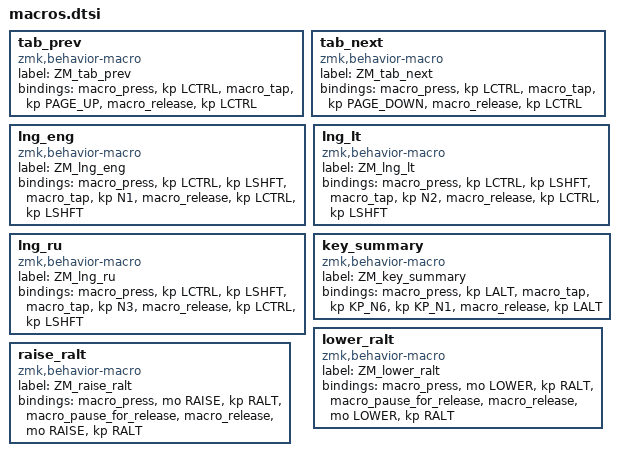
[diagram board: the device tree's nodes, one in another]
 // TAB: PREV
tab_prev: tab_prev {
        label = "ZM_tab_prev";
        compatible = "zmk,behavior-macro";
        #binding-cells = <0>;
        bindings = <&macro_press &kp LCTRL>
                , <&macro_tap &kp PAGE_UP>
                , <&macro_release &kp LCTRL>;
};

// TAB: NEXT
tab_next: tab_next {
        label = "ZM_tab_next";
        compatible = "zmk,behavior-macro";
        #binding-cells = <0>;
        bindings
                = <&macro_press &kp LCTRL>
                , <&macro_tap &kp PAGE_DOWN>
                , <&macro_release &kp LCTRL>;
};

// LANGUAGE: ENG
lng_eng: lng_eng {
        label = "ZM_lng_eng";
        compatible = "zmk,behavior-macro";
        #binding-cells = <0>;
        bindings
                = <&macro_press &kp LCTRL &kp LSHFT>
                , <&macro_tap &kp N1>
                , <&macro_release &kp LCTRL &kp LSHFT>;
};

// LANGUAGE: LT
lng_lt: lng_lt {
        label = "ZM_lng_lt";
        compatible = "zmk,behavior-macro";
        #binding-cells = <0>;
        bindings
                = <&macro_press &kp LCTRL &kp LSHFT>
                , <&macro_tap &kp N2>
                , <&macro_release &kp LCTRL &kp LSHFT>;
};

// LANGUAGE: RU
lng_ru: lng_ru {
        label = "ZM_lng_ru";
        compatible = "zmk,behavior-macro";
        #binding-cells = <0>;
        bindings
                = <&macro_press &kp LCTRL &kp LSHFT>
                , <&macro_tap &kp N3>
                , <&macro_release &kp LCTRL &kp LSHFT>;
};

// ALT CODE: =
key_summary: key_summary {
        label = "ZM_key_summary";
        compatible = "zmk,behavior-macro";
        #binding-cells = <0>;
        bindings
                = <&macro_press &kp LALT>
                , <&macro_tap &kp KP_N6 &kp KP_N1>
                , <&macro_release &kp LALT>;
};

// LOWER WITH ALT (FOR LT)
lower_ralt: lower_ralt {
        label = "ZM_lower_ralt";
        compatible = "zmk,behavior-macro";
        #binding-cells = <0>;
        bindings
                = <&macro_press &mo LOWER &kp RALT>
                , <&macro_pause_for_release>
                , <&macro_release &mo LOWER &kp RALT>;
};

// RAISE WITH ALT (FOR LT)
raise_ralt: raise_ralt {
        label = "ZM_raise_ralt";
        compatible = "zmk,behavior-macro";
        #binding-cells = <0>;
        bindings
                = <&macro_press &mo RAISE &kp RALT>
                , <&macro_pause_for_release>
                , <&macro_release &mo RAISE &kp RALT>;
};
